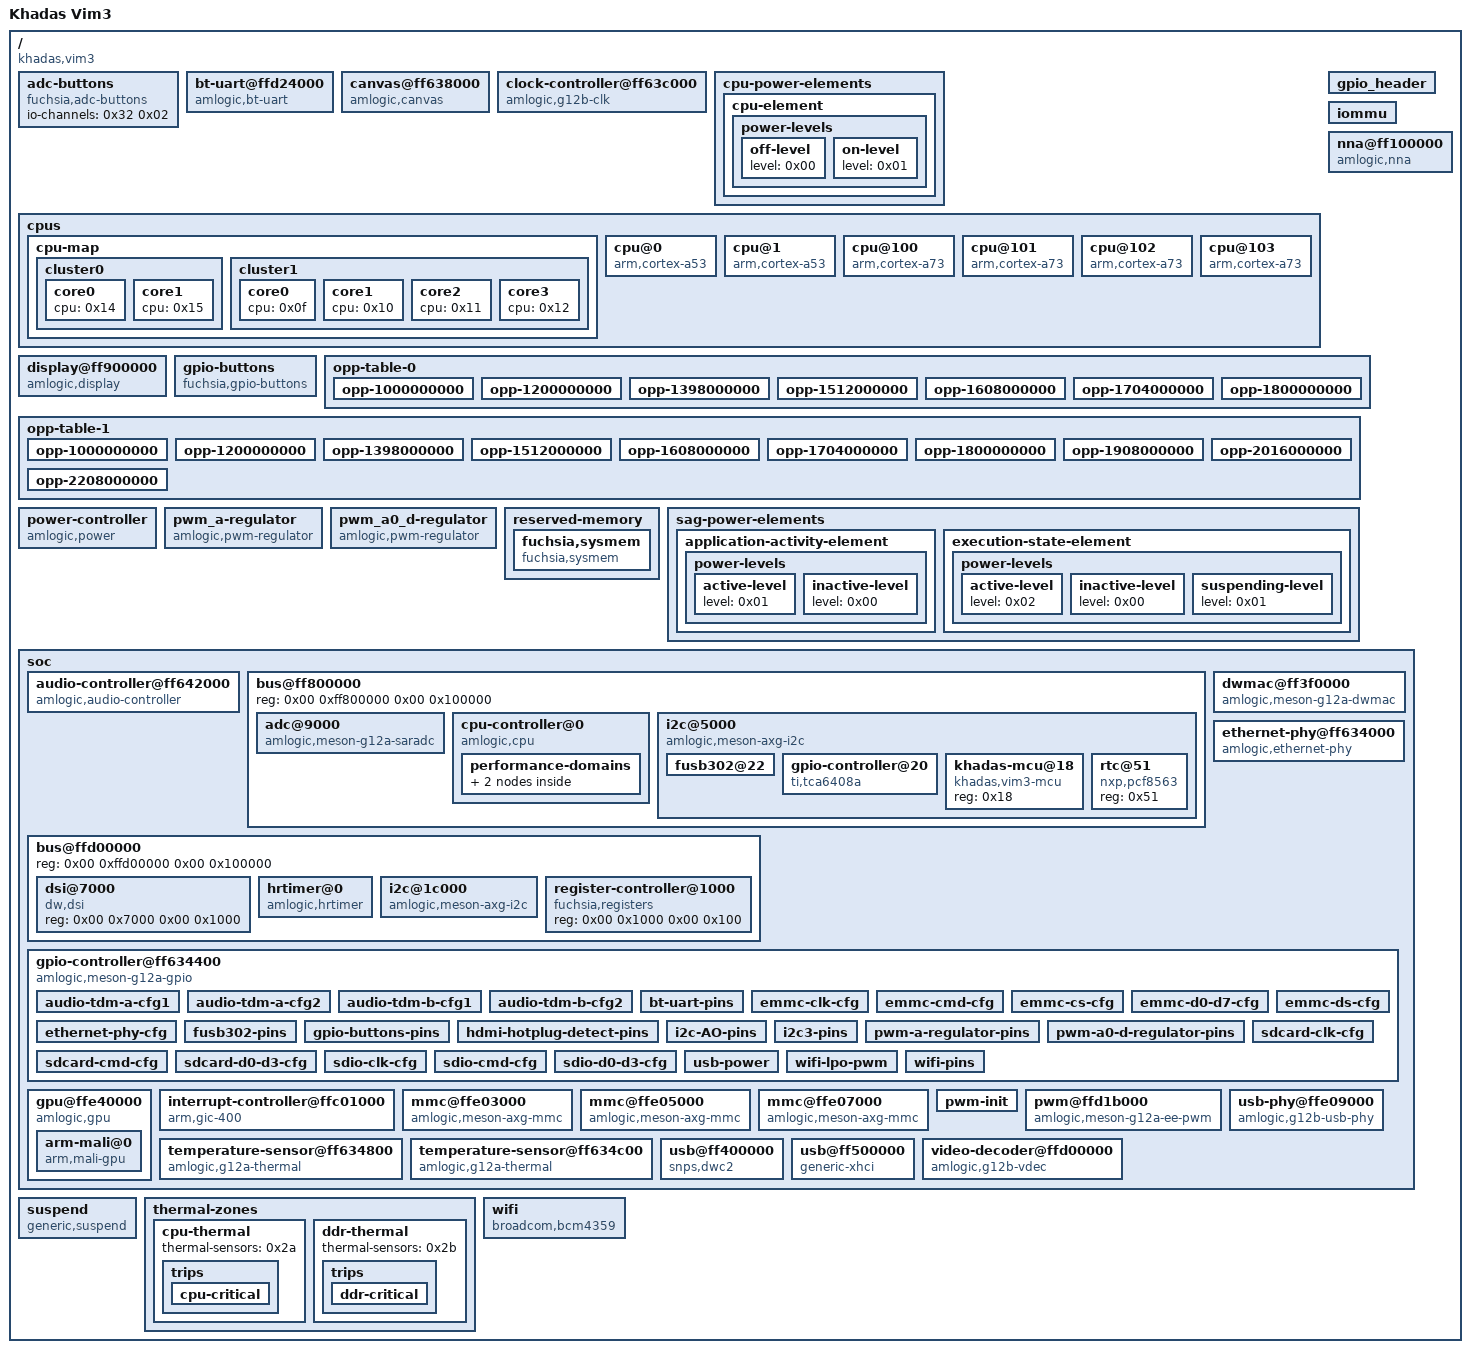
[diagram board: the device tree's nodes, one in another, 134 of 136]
/dts-v1/;

/ {
	#address-cells = <0x02>;
	#size-cells = <0x02>;
	compatible = "khadas,vim3\0amlogic,a311d";
	interrupt-parent = <0x01>;
	model = "Khadas Vim3";

	adc-buttons {
		compatible = "fuchsia,adc-buttons";
		io-channel-names = "VIM3_ADC_BUTTON";
		io-channels = <0x32 0x02>;
	};

	bt-uart@ffd24000 {
		boot-metadata = "CAMm\0\0\0";
		compatible = "amlogic,bt-uart";
		fuchsia,interrupt-wake-vectors = "primary";
		interrupt-names = "primary";
		interrupts = <0x00 0x1a 0x01>;
		pinctrl-0 = <0x33>;
		pwm-init = <0x20>;
		reg = <0x00 0xffd24000 0x00 0x18>;
		serial-port = <0x02 0x06 0x03>;
	};

	canvas@ff638000 {
		compatible = "amlogic,canvas";
		iommus = <0x03 0x0c>;
		phandle = <0x04>;
		reg = <0x00 0xff638000 0x00 0x2000>;
	};

	clock-controller@ff63c000 {
		#clock-cells = <0x01>;
		compatible = "amlogic,g12b-clk";
		phandle = <0x05>;
		reg = <0x00 0xff63c000 0x00 0x2000 0x00 0xff620000 0x00 0x10000 0x00 0xffd18000 0x00 0x1000>;
	};

	cpu-power-elements {

		cpu-element {

			power-levels {

				off-level {
					level = <0x00>;
				};

				on-level {
					level = <0x01>;
				};
			};
		};
	};

	cpus {
		#address-cells = <0x02>;
		#size-cells = <0x00>;

		cpu-map {

			cluster0 {

				core0 {
					cpu = <0x14>;
				};

				core1 {
					cpu = <0x15>;
				};
			};

			cluster1 {

				core0 {
					cpu = <0x0f>;
				};

				core1 {
					cpu = <0x10>;
				};

				core2 {
					cpu = <0x11>;
				};

				core3 {
					cpu = <0x12>;
				};
			};
		};

		cpu@0 {
			compatible = "arm,cortex-a53\0arm,armv8";
			device_type = "cpu";
			enable-method = "psci";
			phandle = <0x14>;
			reg = <0x00 0x00>;
		};

		cpu@1 {
			compatible = "arm,cortex-a53\0arm,armv8";
			device_type = "cpu";
			enable-method = "psci";
			phandle = <0x15>;
			reg = <0x00 0x01>;
		};

		cpu@100 {
			compatible = "arm,cortex-a73\0arm,armv8";
			device_type = "cpu";
			enable-method = "psci";
			phandle = <0x0f>;
			reg = <0x00 0x100>;
		};

		cpu@101 {
			compatible = "arm,cortex-a73\0arm,armv8";
			device_type = "cpu";
			enable-method = "psci";
			phandle = <0x10>;
			reg = <0x00 0x101>;
		};

		cpu@102 {
			compatible = "arm,cortex-a73\0arm,armv8";
			device_type = "cpu";
			enable-method = "psci";
			phandle = <0x11>;
			reg = <0x00 0x102>;
		};

		cpu@103 {
			compatible = "arm,cortex-a73\0arm,armv8";
			device_type = "cpu";
			enable-method = "psci";
			phandle = <0x12>;
			reg = <0x00 0x103>;
		};
	};

	display@ff900000 {
		amlogic,canvas = <0x04>;
		compatible = "amlogic,display";
		gpio-names = "gpio-lcd-reset\0gpio-hdmi-hotplug-detect";
		gpios = <0x2e 0x00 0x00 0x06 0x4e 0x00>;
		interrupt-names = "viu1-vsync\0rdma-done\0vdin1-write-done";
		interrupts = <0x00 0x03 0x01 0x00 0x59 0x01 0x00 0x56 0x01>;
		iommus = <0x03 0x0d>;
		pinctrl-0 = <0x2f>;
		reg = <0x00 0xff900000 0x00 0x40000 0x00 0xffd073c0 0x00 0x40 0x00 0xff644000 0x00 0x2000 0x00 0xffd07000 0x00 0x1000 0x00 0xff63c000 0x00 0x2000 0x00 0xff800000 0x00 0x1000 0x00 0xffd01000 0x00 0x100 0x00 0xff634400 0x00 0x400 0x00 0xff600000 0x00 0x8000 0x00 0xff608000 0x00 0x8000>;
		reg-names = "vpu\0dsi-top\0dsi-phy\0dsi-controller\0hhi\0always-on-rti\0ee-reset\0gpio-mux\0hdmitx-controller\0hdmitx-top";
		smcs = <0x02 0x01 0x00>;
	};

	gpio-buttons {
		compatible = "fuchsia,gpio-buttons";
		gpio-names = "power";
		gpios = <0x06 0x5c 0x00>;
		pinctrl-0 = <0x34>;
	};

	gpio_header {
		gpio-names = "GPIO_HEADER_PIN_37";
		gpios = <0x06 0x50 0x00>;
	};

	iommu {
		#iommu-cells = <0x01>;
		phandle = <0x03>;
	};

	nna@ff100000 {
		compatible = "amlogic,nna";
		interrupts = <0x00 0x93 0x04>;
		iommus = <0x03 0x0b>;
		reg = <0x00 0xff100000 0x00 0x30000 0x00 0xff63c000 0x00 0x2000 0x00 0xff800000 0x00 0x1000 0x00 0xff63c000 0x00 0x1000 0x00 0xff000000 0x00 0x100000>;
		registers = <0x1b 0x88 0x04 0x00 0x1000>;
	};

	opp-table-0 {
		phandle = <0x16>;

		opp-1000000000 {
			opp-hz = <0x00 0x3b9aca00>;
			opp-microvolt = <0xb9ca8>;
		};

		opp-1200000000 {
			opp-hz = <0x00 0x47868c00>;
			opp-microvolt = <0xbeac8>;
		};

		opp-1398000000 {
			opp-hz = <0x00 0x5353c980>;
			opp-microvolt = <0xc5ff8>;
		};

		opp-1512000000 {
			opp-hz = <0x00 0x5a1f4a00>;
			opp-microvolt = <0xd2348>;
		};

		opp-1608000000 {
			opp-hz = <0x00 0x5fd82200>;
			opp-microvolt = <0xdbf88>;
		};

		opp-1704000000 {
			opp-hz = <0x00 0x6590fa00>;
			opp-microvolt = <0xe82d8>;
		};

		opp-1800000000 {
			opp-hz = <0x00 0x6b49d200>;
			opp-microvolt = <0xf4628>;
		};
	};

	opp-table-1 {
		phandle = <0x13>;

		opp-1000000000 {
			opp-hz = <0x00 0x3b9aca00>;
			opp-microvolt = <0xb2778>;
		};

		opp-1200000000 {
			opp-hz = <0x00 0x47868c00>;
			opp-microvolt = <0xb7598>;
		};

		opp-1398000000 {
			opp-hz = <0x00 0x5353c980>;
			opp-microvolt = <0xbc3b8>;
		};

		opp-1512000000 {
			opp-hz = <0x00 0x5a1f4a00>;
			opp-microvolt = <0xbc3b8>;
		};

		opp-1608000000 {
			opp-hz = <0x00 0x5fd82200>;
			opp-microvolt = <0xbeac8>;
		};

		opp-1704000000 {
			opp-hz = <0x00 0x6590fa00>;
			opp-microvolt = <0xc11d8>;
		};

		opp-1800000000 {
			opp-hz = <0x00 0x6b49d200>;
			opp-microvolt = <0xcae18>;
		};

		opp-1908000000 {
			opp-hz = <0x00 0x71b9c500>;
			opp-microvolt = <0xd2348>;
		};

		opp-2016000000 {
			opp-hz = <0x00 0x7829b800>;
			opp-microvolt = <0xde698>;
		};

		opp-2208000000 {
			opp-hz = <0x00 0x839b6800>;
			opp-microvolt = <0xf6d38>;
		};
	};

	power-controller {
		#power-domain-cells = <0x01>;
		compatible = "amlogic,power";
		fuchsia,legacy-power;
		phandle = <0x0e>;
		regulator-names = "vreg-pwm-little\0vreg-pwm-big";
		regulators = <0x2c 0x2d>;
	};

	pwm_a-regulator {
		#regulator-cells = <0x00>;
		compatible = "amlogic,pwm-regulator";
		phandle = <0x2d>;
		pinctrl-0 = <0x31>;
		pwms = <0x18 0x00 0x4e2 0x00>;
		regulator-max-microvolt = <0x100590>;
		regulator-min-microvolt = <0xa8750>;
		regulator-name = "vreg-pwm-big";
		regulator-step-microvolt = <0x3e8>;
	};

	pwm_a0_d-regulator {
		#regulator-cells = <0x00>;
		compatible = "amlogic,pwm-regulator";
		phandle = <0x2c>;
		pinctrl-0 = <0x30>;
		pwms = <0x18 0x09 0x4e2 0x00>;
		regulator-max-microvolt = <0x100590>;
		regulator-min-microvolt = <0xa8750>;
		regulator-name = "vreg-pwm-little";
		regulator-step-microvolt = <0x3e8>;
	};

	reserved-memory {
		#address-cells = <0x02>;
		#size-cells = <0x02>;
		ranges;

		fuchsia,sysmem {
			compatible = "fuchsia,sysmem";
			iommus = <0x03 0x0e>;
			pid = <0x06>;
			size = <0x00 0x00>;
			vid = <0x05>;
		};
	};

	sag-power-elements {

		application-activity-element {

			power-levels {

				active-level {
					level = <0x01>;
				};

				inactive-level {
					level = <0x00>;
				};
			};
		};

		execution-state-element {

			power-levels {

				active-level {
					level = <0x02>;
				};

				inactive-level {
					level = <0x00>;
				};

				suspending-level {
					level = <0x01>;
				};
			};
		};
	};

	soc {
		#address-cells = <0x02>;
		#size-cells = <0x02>;
		ranges;

		audio-controller@ff642000 {
			assigned-clock-rates = <0x2dc6c000>;
			assigned-clocks = <0x05 0x20002>;
			clock-names = "clock-gate\0clock-pll";
			clocks = <0x05 0x1000b 0x05 0x20002>;
			compatible = "amlogic,audio-controller";
			gpio-names = "gpio-tdm-a-sclk\0gpio-tdm-b-sclk";
			gpios = <0x06 0x43 0x00 0x06 0x11 0x00>;
			iommus = <0x03 0x03>;
			pinctrl-0 = <0x08 0x09 0x0a 0x0b>;
			reg = <0x00 0xff642000 0x00 0x2000>;
		};

		bus@ff800000 {
			#address-cells = <0x02>;
			#size-cells = <0x02>;
			ranges = <0x00 0x00 0x00 0xff800000 0x00 0x100000>;
			reg = <0x00 0xff800000 0x00 0x100000>;

			adc@9000 {
				#io-channel-cells = <0x01>;
				compatible = "amlogic,meson-g12a-saradc";
				interrupts = <0x00 0xc8 0x01>;
				phandle = <0x32>;
				reg = <0x00 0x9000 0x00 0x1000 0x00 0x00 0x00 0x1000>;
			};

			cpu-controller@0 {
				clock-names = "sys-pll-div16\0sys-cpu-div16\0sys-cpu-big-clk\0sys-pllb-div16\0sys-cpub-div16\0sys-cpu-little-clk";
				clocks = <0x05 0x10000 0x05 0x10001 0x05 0x100000 0x05 0x10003 0x05 0x10004 0x05 0x100001>;
				compatible = "amlogic,cpu";
				power-domains = <0x0e 0x00 0x0e 0x01>;
				reg = <0x00 0x00 0x00 0x1000>;

				performance-domains {

					a311d-arm-a53-domain {
						cpus = <0x14 0x15>;
						domain-id = <0x02>;
						operating-points = <0x16>;
						relative-performance = <0x70>;
					};

					a311d-arm-a73-domain {
						cpus = <0x0f 0x10 0x11 0x12>;
						domain-id = <0x01>;
						operating-points = <0x13>;
						relative-performance = <0xff>;
					};
				};
			};

			i2c@5000 {
				#address-cells = <0x01>;
				#size-cells = <0x00>;
				compatible = "amlogic,meson-axg-i2c";
				interrupts = <0x00 0xc3 0x01>;
				pinctrl-0 = <0x0c>;
				reg = <0x00 0x5000 0x00 0x20>;

				fusb302@22 {
					gpio-names = "gpio-int";
					gpios = <0x06 0x5d 0x00>;
					pinctrl-0 = <0x0d>;
					reg = <0x22>;
				};

				gpio-controller@20 {
					#gpio-cells = <0x02>;
					compatible = "ti,tca6408a";
					gpio-controller;
					phandle = <0x2e>;
					reg = <0x20>;
				};

				khadas-mcu@18 {
					compatible = "khadas,vim3-mcu";
					reg = <0x18>;
				};

				rtc@51 {
					compatible = "nxp,pcf8563";
					reg = <0x51>;
				};
			};
		};

		bus@ffd00000 {
			#address-cells = <0x02>;
			#size-cells = <0x02>;
			ranges = <0x00 0x00 0x00 0xffd00000 0x00 0x100000>;
			reg = <0x00 0xffd00000 0x00 0x100000>;

			dsi@7000 {
				compatible = "dw,dsi";
				reg = <0x00 0x7000 0x00 0x1000>;
			};

			hrtimer@0 {
				compatible = "amlogic,hrtimer";
				fuchsia,interrupt-wake-vectors = "timer-a\0timer-b\0timer-c\0timer-d\0timer-f\0timer-g\0timer-h\0timer-i";
				interrupt-names = "timer-a\0timer-b\0timer-c\0timer-d\0timer-f\0timer-g\0timer-h\0timer-i";
				interrupts = <0x00 0x0a 0x01 0x00 0x0b 0x01 0x00 0x06 0x01 0x00 0x1d 0x01 0x00 0x3c 0x01 0x00 0x3d 0x01 0x00 0x3e 0x01 0x00 0x3f 0x01>;
				reg = <0x00 0x00 0x00 0x10000>;
			};

			i2c@1c000 {
				#address-cells = <0x01>;
				#size-cells = <0x00>;
				compatible = "amlogic,meson-axg-i2c";
				interrupts = <0x00 0x27 0x01>;
				pinctrl-0 = <0x17>;
				reg = <0x00 0x1c000 0x00 0x20>;
			};

			register-controller@1000 {
				#register-cells = <0x04>;
				compatible = "fuchsia,registers";
				phandle = <0x1b>;
				reg = <0x00 0x1000 0x00 0x100>;
			};
		};

		dwmac@ff3f0000 {
			boot-metadata = "CAMm\0\0\0";
			compatible = "amlogic,meson-g12a-dwmac";
			interrupts = <0x00 0x08 0x04>;
			iommus = <0x03 0x01>;
			phys = <0x02>;
			reg = <0x00 0xff3f0000 0x00 0x10000>;
		};

		ethernet-phy@ff634000 {
			#phy-cells = <0x00>;
			compatible = "amlogic,ethernet-phy";
			gpio-names = "gpio-int";
			gpios = <0x06 0x0e 0x00>;
			phandle = <0x02>;
			pinctrl-0 = <0x07>;
			reg = <0x00 0xff634000 0x00 0x1000 0x00 0xff63c000 0x00 0x2000>;
		};

		gpio-controller@ff634400 {
			#gpio-cells = <0x02>;
			compatible = "amlogic,meson-g12a-gpio";
			fuchsia,interrupt-wake-vectors = "0";
			gpio-controller;
			interrupt-names = "0\01\02\03\04\05\06\07";
			interrupts = <0x00 0x40 0x01 0x00 0x41 0x01 0x00 0x42 0x01 0x00 0x43 0x01 0x00 0x44 0x01 0x00 0x45 0x01 0x00 0x46 0x01 0x00 0x47 0x01>;
			phandle = <0x06>;
			reg = <0x00 0xff634400 0x00 0x400 0x00 0xff800000 0x00 0x1000 0x00 0xffd00000 0x00 0x10000>;

			audio-tdm-a-cfg1 {
				drive-strength-microamp = <0x00 0xbb8>;
				function-id = <0x00 0x01>;
				phandle = <0x08>;
				pins = <0x43 0x42 0x41>;
			};

			audio-tdm-a-cfg2 {
				function-id = <0x00 0x02>;
				phandle = <0x09>;
				pins = <0x40>;
			};

			audio-tdm-b-cfg1 {
				drive-strength-microamp = <0x00 0xbb8>;
				function-id = <0x00 0x01>;
				phandle = <0x0a>;
				pins = <0x11 0x12 0x13>;
			};

			audio-tdm-b-cfg2 {
				function-id = <0x00 0x02>;
				phandle = <0x0b>;
				pins = <0x14>;
			};

			bt-uart-pins {
				function-id = <0x00 0x01>;
				phandle = <0x33>;
				pins = <0x44 0x45 0x46 0x47>;
			};

			emmc-clk-cfg {
				function-id = <0x00 0x01>;
				phandle = <0x25>;
				pins = <0x28>;
			};

			emmc-cmd-cfg {
				function-id = <0x00 0x01>;
				phandle = <0x26>;
				pins = <0x2a>;
			};

			emmc-cs-cfg {
				output-high;
				phandle = <0x28>;
				pins = <0x2e>;
			};

			emmc-d0-d7-cfg {
				function-id = <0x00 0x01>;
				phandle = <0x24>;
				pins = <0x20 0x21 0x22 0x23 0x24 0x25 0x26 0x27>;
			};

			emmc-ds-cfg {
				function-id = <0x00 0x01>;
				phandle = <0x27>;
				pins = <0x2d>;
			};

			ethernet-phy-cfg {
				drive-strength-microamp = <0x00 0x9c4>;
				function-id = <0x00 0x01>;
				phandle = <0x07>;
				pins = <0x00 0x01 0x02 0x03 0x04 0x05 0x06 0x07 0x08 0x09 0x0a 0x0b 0x0c 0x0d>;
			};

			fusb302-pins {
				bias-pull-up;
				output-disable;
				phandle = <0x0d>;
				pins = <0x5d>;
			};

			gpio-buttons-pins {
				bias-disable;
				fuchsia,interrupt-wake-vector;
				function-id = <0x00 0x00>;
				phandle = <0x34>;
				pins = <0x5c>;
			};

			hdmi-hotplug-detect-pins {
				bias-pull-down;
				output-disable;
				phandle = <0x2f>;
				pins = <0x4e>;
			};

			i2c-AO-pins {
				function-id = <0x00 0x01>;
				phandle = <0x0c>;
				pins = <0x57 0x57>;
			};

			i2c3-pins {
				function-id = <0x00 0x02>;
				phandle = <0x17>;
				pins = <0x1f 0x1e>;
			};

			pwm-a-regulator-pins {
				function-id = <0x00 0x03>;
				output-low;
				phandle = <0x31>;
				pins = <0x63>;
			};

			pwm-a0-d-regulator-pins {
				function-id = <0x00 0x03>;
				output-low;
				phandle = <0x30>;
				pins = <0x62>;
			};

			sdcard-clk-cfg {
				function-id = <0x00 0x01>;
				phandle = <0x22>;
				pins = <0x34>;
			};

			sdcard-cmd-cfg {
				function-id = <0x00 0x01>;
				phandle = <0x23>;
				pins = <0x35>;
			};

			sdcard-d0-d3-cfg {
				function-id = <0x00 0x01>;
				phandle = <0x21>;
				pins = <0x30 0x31 0x32 0x33>;
			};

			sdio-clk-cfg {
				bias-disable;
				drive-strength-microamp = <0x00 0xfa0>;
				function-id = <0x00 0x01>;
				phandle = <0x1e>;
				pins = <0x3c>;
			};

			sdio-cmd-cfg {
				bias-disable;
				drive-strength-microamp = <0x00 0xfa0>;
				function-id = <0x00 0x01>;
				phandle = <0x1f>;
				pins = <0x3d>;
			};

			sdio-d0-d3-cfg {
				bias-disable;
				drive-strength-microamp = <0x00 0xfa0>;
				function-id = <0x00 0x01>;
				phandle = <0x1d>;
				pins = <0x38 0x39 0x3a 0x3b>;
			};

			usb-power {
				output-high;
				phandle = <0x1a>;
				pins = <0x16>;
			};

			wifi-lpo-pwm {
				function-id = <0x00 0x01>;
				phandle = <0x19>;
				pins = <0x48>;
			};

			wifi-pins {
				bias-disable;
				phandle = <0x35>;
				pins = <0x3f>;
			};
		};

		gpu@ffe40000 {
			#address-cells = <0x02>;
			#size-cells = <0x02>;
			compatible = "amlogic,gpu";
			phandle = <0x29>;
			ranges = <0x00 0x00 0x00 0xffe40000 0x00 0x40000>;
			reg = <0x00 0xffe40000 0x00 0x40000 0x00 0xff63c000 0x00 0x2000>;
			registers = <0x1b 0x40 0x04 0x00 0x100000 0x1b 0x80 0x04 0x00 0x100000 0x1b 0x48 0x04 0x00 0x4000 0x1b 0x88 0x04 0x00 0x4000>;

			arm-mali@0 {
				compatible = "arm,mali-gpu";
				interrupts = <0x00 0xa2 0x04 0x00 0xa1 0x04 0x00 0xa0 0x04>;
				iommus = <0x03 0x0a>;
				mali-gpu-parent = <0x29>;
				reg = <0x00 0x00 0x00 0x40000>;
			};
		};

		interrupt-controller@ffc01000 {
			#address-cells = <0x00>;
			#interrupt-cells = <0x03>;
			compatible = "arm,gic-400";
			interrupt-controller;
			interrupts = <0x01 0x09 0xff04>;
			phandle = <0x01>;
			reg = <0x00 0xffc01000 0x00 0x1000 0x00 0xffc02000 0x00 0x2000 0x00 0xffc04000 0x00 0x2000 0x00 0xffc06000 0x00 0x2000>;
		};

		mmc@ffe03000 {
			compatible = "amlogic,meson-axg-mmc";
			gpio-names = "gpio-reset";
			gpios = <0x06 0x3e 0x00>;
			interrupts = <0x00 0xbd 0x01>;
			iommus = <0x03 0x07>;
			max-frequency = <0x5f5e100>;
			pinctrl-0 = <0x1d 0x1e 0x1f>;
			pwm-init = <0x20>;
			reg = <0x00 0xffe03000 0x00 0x2000>;
		};

		mmc@ffe05000 {
			compatible = "amlogic,meson-axg-mmc";
			interrupts = <0x00 0xbe 0x01>;
			iommus = <0x03 0x08>;
			max-frequency = <0x2faf080>;
			pinctrl-0 = <0x21 0x22 0x23>;
			reg = <0x00 0xffe05000 0x00 0x2000>;
		};

		mmc@ffe07000 {
			boot-metadata = "TRPm\0\0\0";
			clocks = <0x05 0x1000c>;
			compatible = "amlogic,meson-axg-mmc";
			gpio-names = "gpio-reset";
			gpios = <0x06 0x2c 0x00>;
			interrupts = <0x00 0xbf 0x01>;
			iommus = <0x03 0x09>;
			max-frequency = <0x7270e00>;
			no-mmc-hs400;
			non-removable;
			pinctrl-0 = <0x24 0x25 0x26 0x27 0x28>;
			reg = <0x00 0xffe07000 0x00 0x2000>;
			use-fidl;
		};

		pwm-init {
			gpio-names = "gpio-bt";
			gpios = <0x06 0x49 0x00>;
			phandle = <0x20>;
			pinctrl-0 = <0x19>;
			pwms = <0x18 0x04 0x00 0x00>;
		};

		pwm@ffd1b000 {
			#pwm-cells = <0x03>;
			compatible = "amlogic,meson-g12a-ee-pwm";
			phandle = <0x18>;
			reg = <0x00 0xffd1b000 0x00 0x1000 0x00 0xffd1a000 0x00 0x1000 0x00 0xffd19000 0x00 0x1000 0x00 0xff807000 0x00 0x1000 0x00 0xff802000 0x00 0x1000>;
		};

		temperature-sensor@ff634800 {
			#thermal-sensor-cells = <0x00>;
			assigned-clocks = <0x05 0x1000d>;
			compatible = "amlogic,g12a-thermal";
			interrupts = <0x00 0x23 0x01>;
			phandle = <0x2a>;
			reg = <0x00 0xff634800 0x00 0x80 0x00 0xff800268 0x00 0x04>;
		};

		temperature-sensor@ff634c00 {
			#thermal-sensor-cells = <0x00>;
			assigned-clocks = <0x05 0x1000d>;
			compatible = "amlogic,g12a-thermal";
			interrupts = <0x00 0x24 0x01>;
			phandle = <0x2b>;
			reg = <0x00 0xff634c00 0x00 0x80 0x00 0xff800230 0x00 0x04>;
		};

		usb-phy@ffe09000 {
			#phy-cells = <0x00>;
			assigned-clock-rates = <0x00 0x00 0x5f5e100>;
			assigned-clocks = <0x05 0x10008 0x05 0x10009 0x05 0x20001>;
			compatible = "amlogic,g12b-usb-phy";
			dr_modes = "host\0peripheral\0host";
			interrupts = <0x00 0x10 0x01>;
			iommus = <0x03 0x05>;
			phandle = <0x1c>;
			pinctrl-0 = <0x1a>;
			reg = <0x00 0xffe09000 0x00 0x2000 0x00 0xff636000 0x00 0x2000 0x00 0xff63a000 0x00 0x2000 0x00 0xff646000 0x00 0x2000>;
			reg-names = "usb-ctrl\0usb2-phy\0usb2-otg-phy\0usb3-phy";
			registers = <0x1b 0x08 0x04 0x00 0x10004 0x1b 0x84 0x04 0x00 0x30000>;
		};

		usb@ff400000 {
			boot-metadata = "CAMm\0\0\0\0NLRS\0\0\0";
			compatible = "snps,dwc2";
			dma-burst-len = <0x05>;
			fuchsia,interrupt-wake-vectors = "primary";
			g-np-tx-fifo-size = <0x20>;
			g-rx-fifo-size = <0x100>;
			g-turnaround-time = <0x09>;
			g-tx-fifo-size = <0x80 0x04 0x80 0x80>;
			interrupt-names = "primary";
			interrupts = <0x00 0x1f 0x01>;
			iommus = <0x03 0x04>;
			phy-names = "dwc2-phy";
			phys = <0x1c>;
			reg = <0x00 0xff400000 0x00 0x100000>;
		};

		usb@ff500000 {
			compatible = "generic-xhci";
			fuchsia,interrupt-wake-vectors = "primary";
			interrupt-names = "primary";
			interrupts = <0x00 0x1e 0x01>;
			iommus = <0x03 0x06>;
			phy-names = "xhci-phy";
			phys = <0x1c>;
			reg = <0x00 0xff500000 0x00 0x100000>;
		};

		video-decoder@ffd00000 {
			amlogic,canvas = <0x04>;
			clock-names = "clock-dos-vdec\0clock-dos";
			clocks = <0x05 0x10005 0x05 0x10007>;
			compatible = "amlogic,g12b-vdec";
			interrupts = <0x00 0x17 0x01 0x00 0x20 0x01 0x00 0x2b 0x01 0x00 0x2c 0x01>;
			iommus = <0x03 0x02>;
			reg = <0x00 0xffd00000 0x00 0x100000 0x00 0xff620000 0x00 0x10000 0x00 0xff63c000 0x00 0x2000 0x00 0xff800000 0x00 0x1000 0x00 0xff638000 0x00 0x2000>;
		};
	};

	suspend {
		compatible = "generic,suspend";
	};

	thermal-zones {

		cpu-thermal {
			thermal-sensors = <0x2a>;

			trips {

				cpu-critical {
					temperature = <0x18a88>;
					type = "critical";
				};
			};
		};

		ddr-thermal {
			thermal-sensors = <0x2b>;

			trips {

				ddr-critical {
					temperature = <0x1adb0>;
					type = "critical";
				};
			};
		};
	};

	wifi {
		compatible = "broadcom,bcm4359";
		gpio-names = "gpio-oob";
		gpios = <0x06 0x3f 0x00>;
		pinctrl-0 = <0x35>;
	};
};
